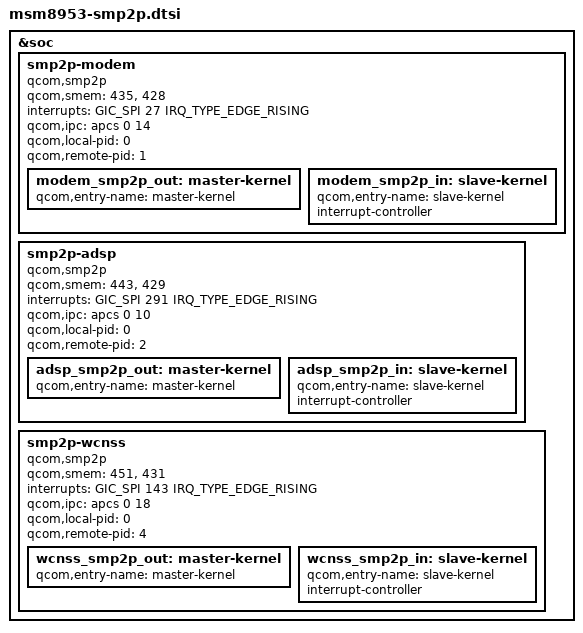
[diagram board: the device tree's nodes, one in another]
&soc {
	smp2p-modem {
		compatible = "qcom,smp2p";
		qcom,smem = <435>, <428>;
		interrupts = <GIC_SPI 27 IRQ_TYPE_EDGE_RISING>;
		qcom,ipc = <&apcs 0 14>;
		qcom,local-pid = <0>;
		qcom,remote-pid = <1>;

		modem_smp2p_out: master-kernel {
			qcom,entry-name = "master-kernel";
			#qcom,smem-state-cells = <1>;
		};

		modem_smp2p_in: slave-kernel {
			qcom,entry-name = "slave-kernel";
			interrupt-controller;
			#interrupt-cells = <2>;
		};
	};

	smp2p-adsp {
		compatible = "qcom,smp2p";
		qcom,smem = <443>, <429>;
		interrupts = <GIC_SPI 291 IRQ_TYPE_EDGE_RISING>;
		qcom,ipc = <&apcs 0 10>;
		qcom,local-pid = <0>;
		qcom,remote-pid = <2>;

		adsp_smp2p_out: master-kernel {
			qcom,entry-name = "master-kernel";
			#qcom,smem-state-cells = <1>;
		};

		adsp_smp2p_in: slave-kernel {
			qcom,entry-name = "slave-kernel";
			interrupt-controller;
			#interrupt-cells = <2>;
		};
	};

	smp2p-wcnss {
		compatible = "qcom,smp2p";
		qcom,smem = <451>, <431>;
		interrupts = <GIC_SPI 143 IRQ_TYPE_EDGE_RISING>;
		qcom,ipc = <&apcs 0 18>;
		qcom,local-pid = <0>;
		qcom,remote-pid = <4>;

		wcnss_smp2p_out: master-kernel {
			qcom,entry-name = "master-kernel";
			#qcom,smem-state-cells = <1>;
		};

		wcnss_smp2p_in: slave-kernel {
			qcom,entry-name = "slave-kernel";
			interrupt-controller;
			#interrupt-cells = <2>;
		};
	};
};
